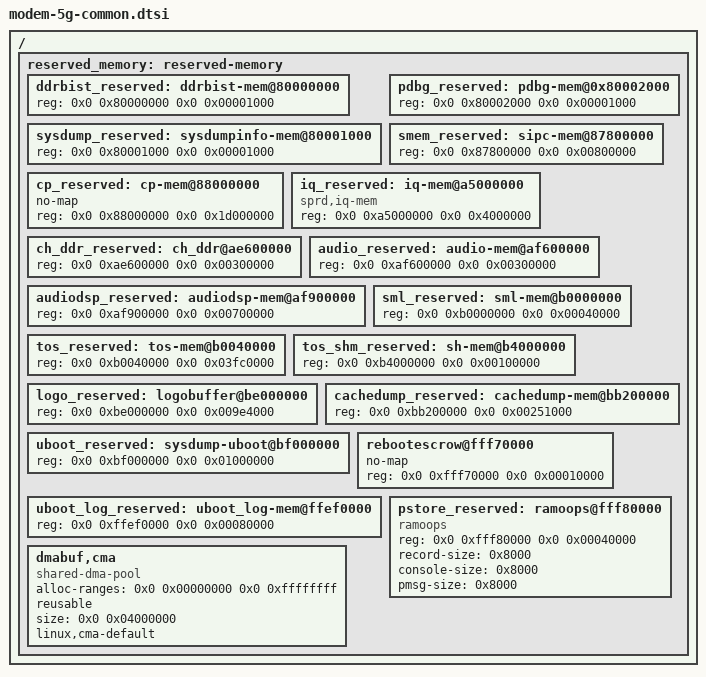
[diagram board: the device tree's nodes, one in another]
// SPDX-License-Identifier: (Licenseref-Unisoc-General-1.0 OR GPL-2.0-only)
/*
 * modem-5g-common.dtsi - Unisoc platform device
 *
 * Copyright 2022 Unisoc(Shanghai) Technologies Co.Ltd
 *
 * Licensed under the Unisoc General Software License, version 1.0 (the
 * License);
 * you may not use this file except in compliance with the License.
 * You may obtain a copy of the License at
 * https://www.unisoc.com/en_us/license/UNISOC_GENERAL_LICENSE_V1.0-EN_US
 * Software distributed under the License is distributed on an "AS IS" BASIS,
 * WITHOUT WARRANTIES OF ANY KIND, either express or implied.
 * See the Unisoc General Software License, version 1.0 for more details.
 *
 * Alternatively you can use and distribute this file under the terms of the
 * GNU General Public License version 2, provided that it has to be used
 *  (including but not limited to combining, linking) with any other file under
 * the GNU General Public License version 2 on platforms that use Unisoc Chips.
 */

/{
	reserved_memory: reserved-memory {
		#address-cells = <2>;
		#size-cells = <2>;
		ranges;

		ddrbist_reserved: ddrbist-mem@80000000 {
			reg = <0x0 0x80000000 0x0 0x00001000>;
		};

		sysdump_reserved: sysdumpinfo-mem@80001000 {
			reg = <0x0 0x80001000 0x0 0x00001000>;
		};

		pdbg_reserved: pdbg-mem@0x80002000 {
			reg = <0x0 0x80002000 0x0 0x00001000>;
		};

		smem_reserved: sipc-mem@87800000 {
			reg = <0x0 0x87800000 0x0 0x00800000>;
		};

		cp_reserved: cp-mem@88000000 {
			no-map;
			reg = <0x0 0x88000000 0x0 0x1d000000>;
		};

		/* Only used for iq, will be removed in normal mode by uboot */
		iq_reserved: iq-mem@a5000000{
			compatible = "sprd,iq-mem";
			reg = <0x0 0xa5000000 0x0 0x4000000>;
		};

		ch_ddr_reserved: ch_ddr@ae600000 {
			reg = <0x0 0xae600000 0x0 0x00300000>;
		};

		audio_reserved: audio-mem@af600000 {
			reg = <0x0 0xaf600000 0x0 0x00300000>;
		};

		audiodsp_reserved: audiodsp-mem@af900000 {
			reg = <0x0 0xaf900000 0x0 0x00700000>;
		};

		/* must be 1M aligned */
		sml_reserved: sml-mem@b0000000 {
			reg = <0x0 0xb0000000 0x0 0x00040000>;
		};

		/* the reg values may be not accurate, they have been fixed in lk !!! */
		tos_reserved: tos-mem@b0040000 {
			reg = <0x0 0xb0040000 0x0 0x03fc0000>;
		};

		tos_shm_reserved: sh-mem@b4000000{
			reg = <0x0 0xb4000000 0x0 0x00100000>;
		};

		logo_reserved: logobuffer@be000000 {
			reg = <0x0 0xbe000000 0x0 0x009e4000>;
		};

		/* Only for debug version, will be removed if user version */
		cachedump_reserved: cachedump-mem@bb200000 {
			reg = <0x0 0xbb200000 0x0 0x00251000>; /* 2372k */
		};

		/* Only for userdebug, will be removed in user mode by lk */
		uboot_reserved: sysdump-uboot@bf000000 {
			reg = <0x0 0xbf000000 0x0 0x01000000>;
		};

		rebootescrow@fff70000 {
			no-map;
			reg = <0x0 0xfff70000 0x0 0x00010000>; /* 64K */
		};

		/* The uboot_log_reserved node is added in lk. base:0xffef0000, size:0x80000 */
		uboot_log_reserved: uboot_log-mem@ffef0000 {
			reg = <0x0 0xffef0000 0x0 0x00080000>;
		};

		pstore_reserved: ramoops@fff80000 {
			compatible = "ramoops";
			reg = <0x0 0xfff80000 0x0 0x00040000>;
			record-size = <0x8000>;
			console-size = <0x8000>;
			pmsg-size = <0x8000>;
		};

		/* global autoconfigured region for contiguous allocations */
		dmabuf,cma {
			compatible = "shared-dma-pool";
			alloc-ranges = <0x0 0x00000000 0x0 0xffffffff>;
			reusable;
			size = <0x0 0x04000000>;
			linux,cma-default;
		};
	};
};

